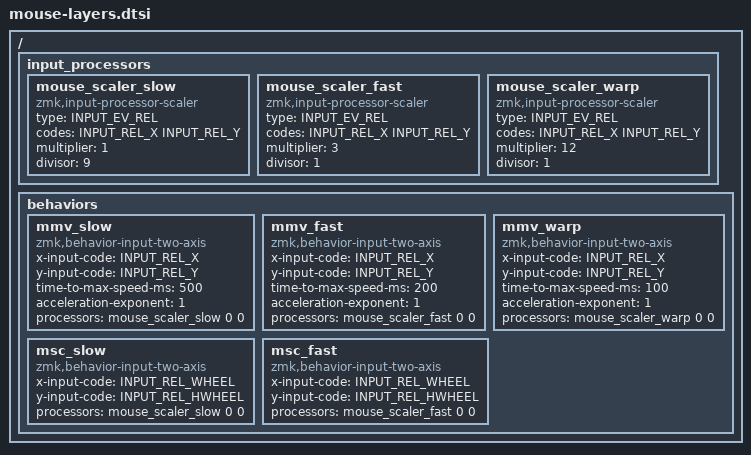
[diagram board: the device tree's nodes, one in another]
// mouse-layers.dtsi
#include <dt-bindings/zmk/mouse.h>
#include <input/input.h>

/ {
    /* Input Processors for Mouse Speed Control */
    input_processors {
        mouse_scaler_slow: mouse_scaler_slow {
            compatible = "zmk,input-processor-scaler";
            #input-processor-cells = <2>;
            type = <INPUT_EV_REL>;
            codes = <INPUT_REL_X INPUT_REL_Y>;
            multiplier = <1>;
            divisor = <9>;  // 1/9 speed (very slow)
        };
        
        mouse_scaler_fast: mouse_scaler_fast {
            compatible = "zmk,input-processor-scaler";
            #input-processor-cells = <2>;
            type = <INPUT_EV_REL>;
            codes = <INPUT_REL_X INPUT_REL_Y>;
            multiplier = <3>;
            divisor = <1>;  // 3x speed
        };
        
        mouse_scaler_warp: mouse_scaler_warp {
            compatible = "zmk,input-processor-scaler";
            #input-processor-cells = <2>;
            type = <INPUT_EV_REL>;
            codes = <INPUT_REL_X INPUT_REL_Y>;
            multiplier = <12>;
            divisor = <1>;  // 12x speed (warp)
        };
    };

    /* Mouse Movement Behaviors with Different Speeds */
    behaviors {
        mmv_slow: mmv_slow {
            compatible = "zmk,behavior-input-two-axis";
            #binding-cells = <1>;
            x-input-code = <INPUT_REL_X>;
            y-input-code = <INPUT_REL_Y>;
            time-to-max-speed-ms = <500>;
            acceleration-exponent = <1>;
            processors = <&mouse_scaler_slow 0 0>;
        };
        
        mmv_fast: mmv_fast {
            compatible = "zmk,behavior-input-two-axis";
            #binding-cells = <1>;
            x-input-code = <INPUT_REL_X>;
            y-input-code = <INPUT_REL_Y>;
            time-to-max-speed-ms = <200>;
            acceleration-exponent = <1>;
            processors = <&mouse_scaler_fast 0 0>;
        };
        
        mmv_warp: mmv_warp {
            compatible = "zmk,behavior-input-two-axis";
            #binding-cells = <1>;
            x-input-code = <INPUT_REL_X>;
            y-input-code = <INPUT_REL_Y>;
            time-to-max-speed-ms = <100>;
            acceleration-exponent = <1>;
            processors = <&mouse_scaler_warp 0 0>;
        };

        /* Optional: Mouse scroll with speed variants */
        msc_slow: msc_slow {
            compatible = "zmk,behavior-input-two-axis";
            #binding-cells = <1>;
            x-input-code = <INPUT_REL_WHEEL>;
            y-input-code = <INPUT_REL_HWHEEL>;
            processors = <&mouse_scaler_slow 0 0>;
        };
        
        msc_fast: msc_fast {
            compatible = "zmk,behavior-input-two-axis";
            #binding-cells = <1>;
            x-input-code = <INPUT_REL_WHEEL>;
            y-input-code = <INPUT_REL_HWHEEL>;
            processors = <&mouse_scaler_fast 0 0>;
        };
    };
};
